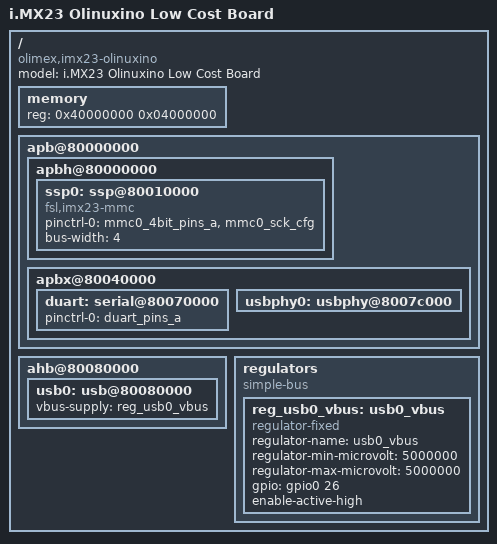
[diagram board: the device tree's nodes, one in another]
/*
 * Copyright 2012 Freescale Semiconductor, Inc.
 *
 * Author: Fabio Estevam <fabio.estevam@freescale.com>
 *
 * The code contained herein is licensed under the GNU General Public
 * License. You may obtain a copy of the GNU General Public License
 * Version 2 or later at the following locations:
 *
 * http://www.opensource.org/licenses/gpl-license.html
 * http://www.gnu.org/copyleft/gpl.html
 */

/dts-v1/;
/include/ "imx23.dtsi"

/ {
	model = "i.MX23 Olinuxino Low Cost Board";
	compatible = "olimex,imx23-olinuxino", "fsl,imx23";

	memory {
		reg = <0x40000000 0x04000000>;
	};

	apb@80000000 {
		apbh@80000000 {
			ssp0: ssp@80010000 {
				compatible = "fsl,imx23-mmc";
				pinctrl-names = "default";
				pinctrl-0 = <&mmc0_4bit_pins_a &mmc0_sck_cfg>;
				bus-width = <4>;
				status = "okay";
			};
		};

		apbx@80040000 {
			duart: serial@80070000 {
				pinctrl-names = "default";
				pinctrl-0 = <&duart_pins_a>;
				status = "okay";
			};

			usbphy0: usbphy@8007c000 {
				status = "okay";
			};
		};
	};

	ahb@80080000 {
		usb0: usb@80080000 {
			vbus-supply = <&reg_usb0_vbus>;
			status = "okay";
		};
	};

	regulators {
		compatible = "simple-bus";

		reg_usb0_vbus: usb0_vbus {
			compatible = "regulator-fixed";
			regulator-name = "usb0_vbus";
			regulator-min-microvolt = <5000000>;
			regulator-max-microvolt = <5000000>;
			gpio = <&gpio0 26 0>;
			enable-active-high;
		};
	};
};
